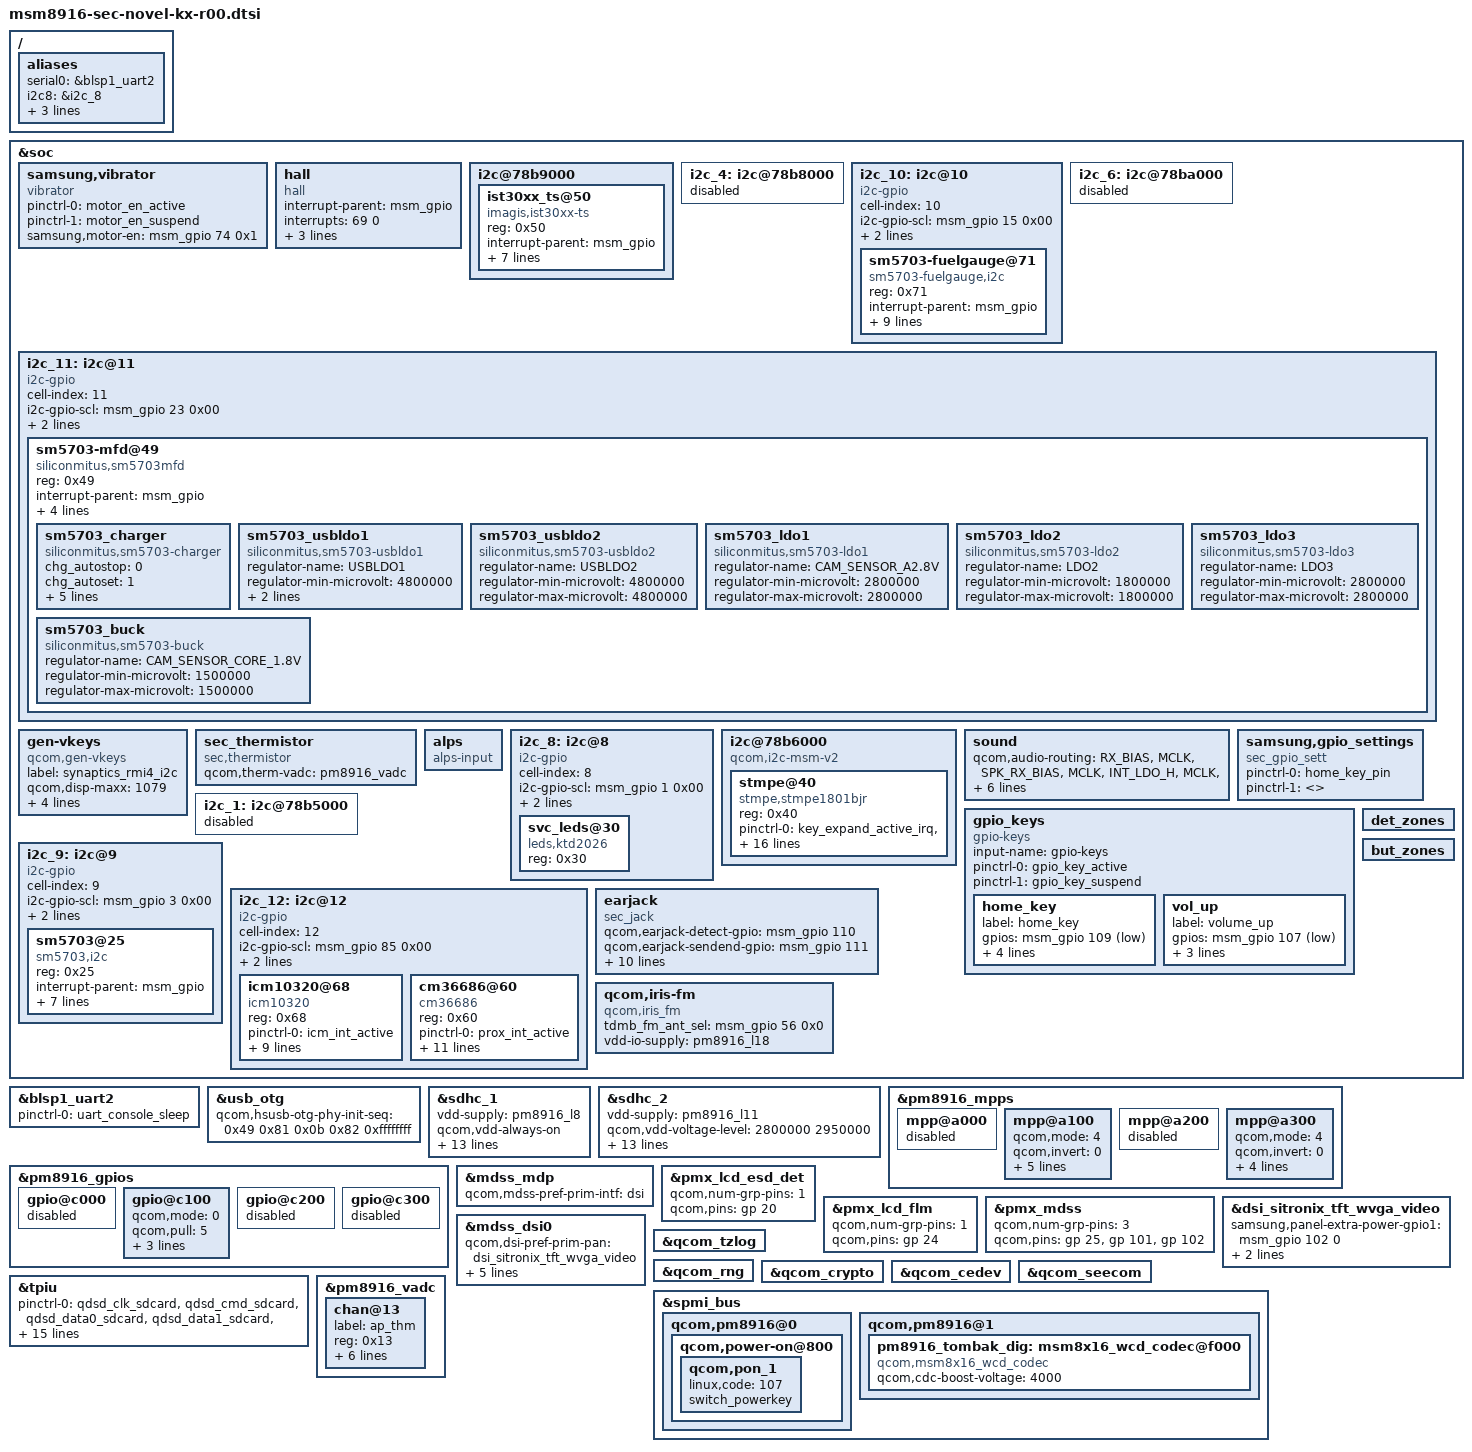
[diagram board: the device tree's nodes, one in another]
/* Copyright (c) 2014, The Linux Foundation. All rights reserved.
 *
 * This program is free software; you can redistribute it and/or modify
 * it under the terms of the GNU General Public License version 2 and
 * only version 2 as published by the Free Software Foundation.
 *
 * This program is distributed in the hope that it will be useful,
 * but WITHOUT ANY WARRANTY; without even the implied warranty of
 * MERCHANTABILITY or FITNESS FOR A PARTICULAR PURPOSE.  See the
 * GNU General Public License for more details.
 */

#include "msm8916.dtsi"
#include "msm8916-pinctrl-sec-novel-kx-r00.dtsi"
#include "msm8916-camera.dtsi"
#include "msm8916-camera-sensor-cdp-novel-r00.dtsi"
#include "msm8916-sec-novel-battery-r00.dtsi"
#include "../../../../../../drivers/video/msm/mdss/samsung/SC7798D_BV038WVM/dsi_panel_SC7798D_BV038WVM_wvga_video.dtsi"
#include "msm8916-tdmb-novel-r00.dtsi"

/ {
	aliases {
		serial0 = &blsp1_uart2;

		/*i2c-gpio bus_id*/
              //i2c7 = &i2c_7;
                i2c8 = &i2c_8;
		i2c9 = &i2c_9;
		i2c10 = &i2c_10;
		i2c11 = &i2c_11;
	};
};

&soc {
	samsung,vibrator {
		pinctrl-names = "tlmm_motor_en_active","tlmm_motor_en_suspend";
		pinctrl-0 = <&motor_en_active>;
		pinctrl-1 = <&motor_en_suspend>;
		compatible = "vibrator";
		samsung,motor-en = <&msm_gpio 74 0x1>;
		status = "ok";
	};

	hall {
		status = "okay";
		compatible = "hall";
		interrupt-parent = <&msm_gpio>;
		interrupts = <69 0>;
		hall,gpio_flip_cover = <&msm_gpio 69 0>;
		pinctrl-names = "pmx_hall_ic_pin";
		pinctrl-0 = <&hall_ic_pin>;
		hall,folder_type;
	};

	i2c@78b9000 { /* BLSP1 QUP5 */
	status = "ok";
		ist30xx_ts@50 {
			compatible = "imagis,ist30xx-ts";
			reg = <0x50>;
			interrupt-parent = <&msm_gpio>;
			interrupts = <13 0>;
			pinctrl-names = "tsp_int_active", "tsp_en_gpio_active", "tsp_en_gpio_suspend";
			pinctrl-0 = <&int_active>;
			pinctrl-1 = <&tsp_en_active>;
			pinctrl-2 = <&tsp_en_suspend>;

			vdd_en-gpio = <&msm_gpio 75 0x01>;
			imagis,irq-gpio = <&msm_gpio 13 0x00>;
			imagis,i2c-pull-up = <1>;
		};
	};

	i2c_4: i2c@78b8000 { /* BLSP1 QUP4 */
		status="disable";
	};

	i2c_10:i2c@10 {
		cell-index = <10>;
		compatible = "i2c-gpio";
		i2c-gpio-scl = <&msm_gpio 15 0x00>;
		i2c-gpio-sda = <&msm_gpio 14 0x00>;
		i2c-gpio,delay-us = <2>;
		#address-cells = <1>;
		#size-cells = <0>;

		sm5703-fuelgauge@71{
			compatible = "sm5703-fuelgauge,i2c";
			reg = <0x71>;
			interrupt-parent = <&msm_gpio>;
			pinctrl-names = "default";
			pinctrl-0 = <&fg_i2c_active &fuel_int_active>;
			fuelgauge,irqf = "IRQF_TRIGGER_FALLING + IRQF_ONESHOT + IRQF_NO_SUSPEND";
			fuelgauge,fuel_int = <&msm_gpio 121 0x1>;
			fuelgauge,capacity_max = <1000>;
			fuelgauge,capacity_max_margin = <50>;
			fuelgauge,capacity_min = <0>;
			fuelgauge,capacity_calculation_type = <0x17>;
			fuelgauge,fuel_alert_soc = <1>;
		};
	};

	i2c_6: i2c@78ba000 { /* BLSP1 QUP6 */
		status="disable";
	};

	i2c_11:i2c@11 {
		cell-index = <11>;
		compatible = "i2c-gpio";
		i2c-gpio-scl = <&msm_gpio 23 0x00>;
		i2c-gpio-sda = <&msm_gpio 22 0x00>;
		i2c-gpio,delay-us = <2>;
		#address-cells = <1>;
		#size-cells = <0>;

		sm5703-mfd@49{
			compatible = "siliconmitus,sm5703mfd";
			reg = <0x49>;
			interrupt-parent = <&msm_gpio>;
			sm5703,irq-gpio = <&msm_gpio 62 0x00>;
			pinctrl-names = "default";
			pinctrl-0 = <&chg_i2c_active &charger_int_active &if_pmic_rst_active &chg_en_active>;
			sm5703,mrstb-gpio = <&msm_gpio 38 0x00>;

			sm5703_charger {
				compatible = "siliconmitus,sm5703-charger";
				chg_autostop = <0>;
				chg_autoset = <1>;
				chg_aiclen = <1>;
				chg_aiclth = <4500>;
				fg_vol_val = <4350>;
				fg_soc_val = <95>;
				fg_curr_avr_val = <150>;
			};

			sm5703_usbldo1 {
				compatible = "siliconmitus,sm5703-usbldo1";
				regulator-name = "USBLDO1"; /* change name by yourself */
				regulator-min-microvolt = <4800000>;
				regulator-max-microvolt = <4800000>; /* max == min then apply_uV = 1 */
				/* regulator-microvolt-offset = < >; optional*/
				/* regulator-boot-on = "yes"; optional, exist = enabled */
				regulator-always-on = "yes";
				/* regulator-ramp-delay = <100>; optional*/

			};
			sm5703_usbldo2 {
				compatible = "siliconmitus,sm5703-usbldo2";
				regulator-name = "USBLDO2"; /* change name by yourself */
				regulator-min-microvolt = <4800000>;
				regulator-max-microvolt = <4800000>; /* max == min then apply_uV = 1 */
				/* regulator-microvolt-offset = < >; optional*/
				/* regulator-boot-on = "yes"; optional, exist = enabled */
				/* regulator-always-on = "yes"; optional, exist = enabled */
				/* regulator-ramp-delay = <100>; optional*/

			};
			sm5703_ldo1 {
				compatible = "siliconmitus,sm5703-ldo1";
				regulator-name = "CAM_SENSOR_A2.8V"; /* change name by yourself */
				regulator-min-microvolt = <2800000>;
				regulator-max-microvolt = <2800000>; /* max == min then apply_uV = 1 */
				/* regulator-microvolt-offset = < >; optional*/
				/* regulator-boot-on = "yes"; optional, exist = enabled */
				/* regulator-always-on = "yes"; optional, exist = enabled */
				/* regulator-ramp-delay = <100>; optional*/
			};

			sm5703_ldo2 {
				compatible = "siliconmitus,sm5703-ldo2";
				regulator-name = "LDO2"; /* change name by yourself */
				regulator-min-microvolt = <1800000>;
				regulator-max-microvolt = <1800000>; /* max == min then apply_uV = 1 */
				/* regulator-microvolt-offset = < >; optional*/
				/* regulator-boot-on = "yes"; optional, exist = enabled */
				/* regulator-always-on = "yes"; optional, exist = enabled */
				/* regulator-ramp-delay = <100>; optional*/
			};

			sm5703_ldo3 {
				compatible = "siliconmitus,sm5703-ldo3";
				regulator-name = "LDO3"; /* change name by yourself */
				regulator-min-microvolt = <2800000>;
				regulator-max-microvolt = <2800000>; /* max == min then apply_uV = 1 */
				/* regulator-microvolt-offset = < >; optional*/
				/* regulator-boot-on = "yes"; optional, exist = enabled */
				/* regulator-always-on = "yes"; optional, exist = enabled */
				/* regulator-ramp-delay = <100>; optional*/
			};

			sm5703_buck {
				compatible = "siliconmitus,sm5703-buck";
				regulator-name = "CAM_SENSOR_CORE_1.8V"; /* change name by yourself */
				regulator-min-microvolt = <1500000>;
				regulator-max-microvolt = <1500000>; /* max == min then apply_uV = 1 */
				/* regulator-microvolt-offset = < >; optional*/
				/* regulator-boot-on = "yes"; optional, exist = enabled */
				/* regulator-always-on = "yes"; optional, exist = enabled */
				/* regulator-ramp-delay = <100>; optional*/
			};
		};
	};

	gen-vkeys {
		compatible = "qcom,gen-vkeys";
		label = "synaptics_rmi4_i2c";
		qcom,disp-maxx = <1079>;
		qcom,disp-maxy = <1919>;
		qcom,panel-maxx = <1079>;
		qcom,panel-maxy = <2084>;
		qcom,key-codes = <158 139 172 217>;
	};

	sec_thermistor {
		compatible = "sec,thermistor";
		qcom,therm-vadc = <&pm8916_vadc>;
	};

	alps {
			compatible = "alps-input";
	};

	i2c_8: i2c@8 {
		cell-index = <8>;
		compatible = "i2c-gpio";
		i2c-gpio-scl = <&msm_gpio 1 0x00>;
		i2c-gpio-sda = <&msm_gpio 0 0x00>;
		i2c-gpio,delay-us = <2>;
		#address-cells = <1>;
		#size-cells = <0>;
		svc_leds@30{
			compatible = "leds,ktd2026";
			reg = <0x30>;
		};
	};

	i2c@78b6000 { /* BLSP1 QUP2 */
		compatible = "qcom,i2c-msm-v2";

		stmpe@40 {
			compatible = "stmpe,stmpe1801bjr";
			reg = <0x40>;
			pinctrl-names = "default";
			pinctrl-0 = <&key_expand_active_irq &key_expand_active_rst>;
			interrupt-parent = <&msm_gpio>;
			interrupts = <34 0>;
			stmpe,vdd-supply = <&pm8916_l5>;
			stmpe,irq_gpio = <&msm_gpio 34 0x00>;
//			stmpe,sda_gpio = <&msm_gpio 6 0x00>;
//			stmpe,scl_gpio = <&msm_gpio 7 0x00>;
//			stmpe,rst_gpio = <&msm_gpio 105 0x00>;
			stmpe,led_en-gpio = <&msm_gpio 108 0x00>;
			stmpe,block_type = <2>; // STMPE1801_BLOCK_GPIO : 1 / STMPE1801_BLOCK_KEY : 2
			stmpe,debounce = <6>; // 30us : 0 / 90us : 2 / 150us : 4 / 210us : 6
			stmpe,freq = <3>; // 60hz : 0 / 30hz : 1 / 15hz : 2 / 275hz : 3
			stmpe,scan_cnt = <2>;
			stmpe,repeat = <0>;
			stmpe,keypad-project = "novel_3x4-keypad";

			keypad,num-rows = <5>;
			keypad,num-columns = <6>;  //  row   colume   keycode
			linux,keymap = <0x000000fe //   0       0     KEY_RECENT(254)
					0x000100ac //   0       1     KEY_HOME(172)
					0x0002009e //   0       2     KEY_BACK(158)
					0x000300e7 //   0       3     KEY_SEND(231)
					0x000400df //   0       4     KEY_CANCEL(223)
					0x00050000 //   0       5     KEY_RESERVED(0)
					0x0100018b //   1       0     KEY_LIST(0x18b)
					0x01010067 //   1       1     KEY_UP(103)
					0x010200d4 //   1       2     KEY_CAMERA(212)
					0x01030002 //   1       3     KEY_1(2)
					0x01040003 //   1       4     KEY_2(3)
					0x01050004 //   1       5     KEY_3(4)
					0x02000069 //   2       0     KEY_LEFT(105)
					0x02010160 //   2       1     KEY_OK(0x160)
					0x0202006a //   2       2     KEY_RIGHT(106)
					0x02030005 //   2       3     KEY_4(5)
					0x02040006 //   2       4     KEY_5(6)
					0x02050007 //   2       5     KEY_6(7)
					0x03000000 //   3       0     KEY_RESERVED(0)
					0x03010000 //   3       1     KEY_RESERVED(0)
					0x03020000 //   3       2     KEY_RESERVED(0)
					0x03030008 //   3       3     KEY_7(8)
					0x03040009 //   3       4     KEY_8(9)
					0x0305000a //   3       5     KEY_9(10)
					0x040001ae //   4       0     KEY_MESSENGER(0x1ae)
					0x0401006c //   4       1     KEY_DOWN(108)
					0x04020244 //   4       2     R_SOFT -> KEY_APPSELECT(0x244)
					0x0403020a //   4       3     KEY_NUMERIC_STAR(0x20a)
					0x0404000b //   4       4     KEY_0(11)
					0x0405020b >;//   4       5     KEY_NUMERIC_POUND(0x20b)
		};
	};

	/* Over-riding model specific changes */
	sound {
		qcom,audio-routing =
			"RX_BIAS", "MCLK",
			"SPK_RX_BIAS", "MCLK",
			"INT_LDO_H", "MCLK",
			"MIC BIAS External", "Handset Mic",
			"MIC BIAS External", "Secondary Mic",
			"AMIC1", "MIC BIAS External",
			"AMIC2", "Headset Mic",
			"AMIC3", "MIC BIAS External";
		pinctrl-names = "cdc_lines_act",
				"cdc_lines_sus";
		pinctrl-0 = <&cdc_pdm_lines_act>;
		pinctrl-1 = <&cdc_pdm_lines_sus>;
	};

	samsung,gpio_settings{
		compatible = "sec_gpio_sett";
		pinctrl-names = "sec_gpio_active","sec_gpio_suspend";
		pinctrl-0 = <&home_key_pin>;
		pinctrl-1 = <>;
	};

};

&blsp1_uart2 {
	status = "ok";
	pinctrl-names = "default";
	pinctrl-0 = <&uart_console_sleep>;
};

&soc {
	gpio_keys {
		compatible = "gpio-keys";
		input-name = "gpio-keys";
		pinctrl-names = "tlmm_gpio_key_active","tlmm_gpio_key_suspend";
		pinctrl-0 = <&gpio_key_active>;
		pinctrl-1 = <&gpio_key_suspend>;

		home_key {
			label = "home_key";
			gpios = <&msm_gpio 109 0x1>;
			linux,input-type = <1>;
			linux,code = <172>;
			gpio-key,wakeup;
			debounce-interval = <15>;
		};
		vol_up {
			label = "volume_up";
			gpios = <&msm_gpio 107 0x1>;
			linux,input-type = <1>;
			linux,code = <115>;
			debounce-interval = <15>;
		};
	};

	i2c_1: i2c@78b5000 { /* BLSP1 QUP1 */
		status="disable";
	};

	i2c_9:i2c@9 { /*SM5703 GPIO-I2C*/
		cell-index = <9>;
		compatible = "i2c-gpio";
		i2c-gpio-scl = <&msm_gpio 3 0x00>;
		i2c-gpio-sda = <&msm_gpio 2 0x00>;
		i2c-gpio,delay-us = <2>;
		#address-cells = <1>;
		#size-cells = <0>;

		sm5703@25{
			compatible = "sm5703,i2c";
			reg = <0x25>;
			interrupt-parent = <&msm_gpio>;
			interrupts= <12 0>;
			sm5703,irq-gpio = <&msm_gpio 12 0x00>;
			sm5703,gpio-sda = <&msm_gpio 2 0x00>;
			sm5703,gpio-scl = <&msm_gpio 3 0x00>;
			sm5703,uarton-gpio = <&msm_gpio 114 0x00>;
			pinctrl-names = "sm5703_i2c_active","sm5703_i2c_suspend";
			pinctrl-0 = <&muic_i2c_active>;
			pinctrl-1 = <&muic_i2c_suspend>;
		};
	};

	i2c_12: i2c@12 {
		cell-index = <12>;
		compatible = "i2c-gpio";
		i2c-gpio-scl = <&msm_gpio 85 0x00>;
		i2c-gpio-sda = <&msm_gpio 84 0x00>;
		i2c-gpio,delay-us = <1>;
		#address-cells = <1>;
		#size-cells = <0>;

		icm10320@68 {
			compatible = "icm10320";
			reg = <0x68>;
			pinctrl-names = "icm_active","icm_suspend";
			pinctrl-0 = <&icm_int_active>;
			pinctrl-1 = <&icm_int_suspend>;
			interrupt-parent = <&msm_gpio>;
			interrupts = <115 0>;
			inv,irq_gpio = <&msm_gpio 115 0x0>;
			inv,int_config = <0>;
			inv,level_shifter = <0>;
			inv,orientation = <1 0 1 0 1 1 1 1 0>;
			inv,vdd-supply = <&pm8916_l17>;
			inv,vio-supply = <&pm8916_l5>;
		};

		cm36686@60 {
			compatible = "cm36686";
			reg = <0x60>;
			pinctrl-names = "prox_active","prox_suspend";
			pinctrl-0 = <&prox_int_active>;
			pinctrl-1 = <&prox_int_suspend>;
			interrupt-parent = <&msm_gpio>;
			interrupts = <113 0>;
			cm36686,irq_gpio = <&msm_gpio 113 0x1>;
			cm36686,leden_gpio = <&msm_gpio 60 0x1>;
			cm36686,default_hi_thd = <14>;
			cm36686,default_low_thd = <8>;
			cm36686,cancel_hi_thd = <10>;
			cm36686,cancel_low_thd = <5>;
			reg_vdd-supply = <&pm8916_l17>;
			reg_vio-supply = <&pm8916_l5>;
			status = "okay";
		};
	};

	det_zones: det_zones {
		#list-det-cells = <4>;
	};

	but_zones: but_zones {
		#list-but-cells = <3>;
	};

	earjack {
		compatible = "sec_jack";
		qcom,earjack-detect-gpio = <&msm_gpio 110 0x0>;
		qcom,earjack-sendend-gpio = <&msm_gpio 111 0x0>;
		qcom,earjack-read-vadc = <&pm8916_vadc>;

		det-zones-list = <&det_zones 0 10000 10 0>,
						 <&det_zones 975 10000 10 0>,
						 <&det_zones 976 10000 10 1>,
						 <&det_zones 1810 10000 10 1>;
		but-zones-list = <&but_zones 0 0 339>,
						 <&but_zones 1 340 479>,
						 <&but_zones 2 480 999>;
		mpp-channel-scaling = <2 1 1>;
		pinctrl-names = "earjack_gpio_active","earjack_gpio_suspend";
		pinctrl-0 = <&earjack_det_act &earjack_switch_act>;
		pinctrl-1 = <&earjack_det_sus &earjack_switch_sus>;
	};

	qcom,iris-fm {
		compatible = "qcom,iris_fm";
		tdmb_fm_ant_sel = <&msm_gpio 56 0x0>;
		vdd-io-supply = <&pm8916_l18>;
	};
};

&usb_otg {
	qcom,hsusb-otg-phy-init-seq =
					<0x49 0x81 0x0b 0x82 0xffffffff>;
};

&sdhc_1 {
	vdd-supply = <&pm8916_l8>;
	qcom,vdd-always-on;
	qcom,vdd-lpm-sup;
	qcom,vdd-voltage-level = <2900000 2900000>;
	qcom,vdd-current-level = <200 400000>;

	vdd-io-supply = <&pm8916_l5>;
	qcom,vdd-io-always-on;
	qcom,vdd-io-lpm-sup;
	qcom,vdd-io-voltage-level = <1800000 1800000>;
	qcom,vdd-io-current-level = <200 60000>;

	pinctrl-names = "active", "sleep";
	pinctrl-0 = <&sdc1_clk_on &sdc1_cmd_on &sdc1_data_on>;
	pinctrl-1 = <&sdc1_clk_off &sdc1_cmd_off &sdc1_data_off>;

	qcom,nonremovable;

	status = "ok";
};

&sdhc_2 {
	vdd-supply = <&pm8916_l11>;
	qcom,vdd-voltage-level = <2800000 2950000>;
	qcom,vdd-current-level = <15000 400000>;

	vdd-io-supply = <&pm8916_l12>;
	qcom,vdd-io-voltage-level = <1800000 2950000>;
	qcom,vdd-io-current-level = <200 50000>;

	pinctrl-names = "active", "sleep";
	pinctrl-0 = <&sdc2_clk_on &sdc2_cmd_on &sdc2_data_on &sdc2_cd_on>;
	pinctrl-1 = <&sdc2_clk_off &sdc2_cmd_off &sdc2_data_off &sdc2_cd_off>;

	#address-cells = <0>;
	interrupt-parent = <&sdhc_2>;
	interrupts = <0 1 2>;
	#interrupt-cells = <1>;
	interrupt-map-mask = <0xffffffff>;
	interrupt-map = <0 &intc 0 125 0
			1 &intc 0 221 0
			2 &msm_gpio 38 0>;
	interrupt-names = "hc_irq", "pwr_irq", "status_irq";
	//cd-gpios = <&msm_gpio 38 0x1>;

	status = "ok";
};

&pm8916_mpps {
	mpp@a000 { /* MPP 1 */
		/* VDD_PX */
		status = "disabled";
	};

	mpp@a100 { /* MPP 2 */
		status = "ok";
		qcom,mode = <4>; // AIN input
		qcom,invert = <0>; //No Invert
		qcom,output-type = <0>; //CMOS
		qcom,vin-sel = <2>; //PM8971_S3 1.8v
		qcom,src-sel = <0>; //MPP Constant
		qcom,ain-route = <1>; // QPNP_PIN_AIN_AMUX_CH6 = 1 for MPP2
		qcom,master-en = <1>; // Function constant
	};

	mpp@a200 { /* MPP 3 */
		/* VREF DAC */
		status = "disabled";
	};

	mpp@a300 { /* MPP 4 */
		status = "ok";
		qcom,mode = <4>; // AIN input
		qcom,invert = <0>; //No Invert
		qcom,output-type = <0>; //CMOS
		qcom,src-sel = <0>; //MPP Constant
		qcom,ain-route = <3>; // QPNP_PIN_AIN_AMUX_CH8 = 3 for MPP4
		qcom,master-en = <1>; // Function constant
	};
};

&pm8916_gpios {
	gpio@c000 { /* GPIO 1 */
		/* Battery UICC Alarm */
		status = "disabled";
	};

	gpio@c100 { /* GPIO 2 */
		/* NFC_CLK_REQ */
		qcom,mode = <0>; /* QPNP_PIN_MODE_DIG_IN */
		qcom,pull = <5>; /* QPNP_PIN_PULL_NO */
		qcom,vin-sel = <2>; /* QPNP_PIN_VIN2 */
		qcom,src-sel = <2>; /* QPNP_PIN_SEL_FUNC_1 */
		qcom,master-en = <1>;
	};

	gpio@c200 { /* GPIO 3 */
		/* External regulator control for WTR */
		status = "disabled";
	};

	gpio@c300 { /* GPIO 4 */
		/* External regulator control for APC */
		status = "disabled";
	};
};

&mdss_mdp {
       qcom,mdss-pref-prim-intf = "dsi";
};

&pmx_lcd_esd_det {
	qcom,num-grp-pins = <1>;
	qcom,pins = <&gp 20>;
};

&pmx_lcd_flm {
	qcom,num-grp-pins = <1>;
	qcom,pins = <&gp 24>;
};

&pmx_mdss {
                 qcom,num-grp-pins = <3>;
                 qcom,pins = <&gp 25>, <&gp 101>, <&gp 102>;
};
&dsi_sitronix_tft_wvga_video {
	samsung,panel-extra-power-gpio1 = <&msm_gpio 102 0>;
	samsung,panel-extra-power-gpio2 = <&msm_gpio 101 0>;
};
&mdss_dsi0 {
	qcom,dsi-pref-prim-pan = <&dsi_sitronix_tft_wvga_video>;
	pinctrl-names = "mdss_default", "mdss_sleep";
	pinctrl-0 = <&mdss_dsi_active &lcd_esd_det_active &lcd_flm_active>;
	pinctrl-1 = <&mdss_dsi_suspend &lcd_esd_det_suspend &lcd_flm_suspend>;
	qcom,platform-reset-gpio = <&msm_gpio 25 0>;
};

&qcom_tzlog {
	status = "okay";
};

&qcom_rng {
	status = "okay";
};

&qcom_crypto {
	status = "okay";
};

&qcom_cedev {
	status = "okay";
};

&qcom_seecom {
	status = "okay";
};

/* CoreSight */
&tpiu {
      pinctrl-names = "sdcard", "trace", "swduart",
		      "swdtrc", "jtag", "spmi";
       /* NIDnT */
      pinctrl-0 = <&qdsd_clk_sdcard &qdsd_cmd_sdcard
                  &qdsd_data0_sdcard &qdsd_data1_sdcard
                  &qdsd_data2_sdcard &qdsd_data3_sdcard>;
      pinctrl-1 = <&qdsd_clk_trace &qdsd_cmd_trace
                  &qdsd_data0_trace &qdsd_data1_trace
                  &qdsd_data2_trace &qdsd_data3_trace>;
      pinctrl-2 = <&qdsd_cmd_swduart &qdsd_data0_swduart
                  &qdsd_data1_swduart &qdsd_data2_swduart
                  &qdsd_data3_swduart>;
      pinctrl-3 = <&qdsd_clk_swdtrc &qdsd_cmd_swdtrc
                  &qdsd_data0_swdtrc &qdsd_data1_swdtrc
                  &qdsd_data2_swdtrc &qdsd_data3_swdtrc>;
      pinctrl-4 = <&qdsd_cmd_jtag &qdsd_data0_jtag
                  &qdsd_data1_jtag &qdsd_data2_jtag
                  &qdsd_data3_jtag>;
      pinctrl-5 = <&qdsd_clk_spmi &qdsd_cmd_spmi
                  &qdsd_data0_spmi &qdsd_data3_spmi>;
};

&pm8916_vadc {
	chan@13 {
		label = "ap_thm";
		reg = <0x13>; // channel 19 for MPP4 , 1:1scale
		qcom,decimation = <0>;
		qcom,pre-div-channel-scaling = <0>; // 1:1scale
		qcom,calibration-type = "ratiometric";
		qcom,scale-function = <1>;
		qcom,hw-settle-time = <2>;
		qcom,fast-avg-setup = <0>;
	};
};

&spmi_bus {
	qcom,pm8916@0 {
		qcom,power-on@800 {
			qcom,pon_1 {
				linux,code = <107>;
				switch_powerkey;
			};
		};
	};
	qcom,pm8916@1 {
		pm8916_tombak_dig: msm8x16_wcd_codec@f000{
			compatible = "qcom,msm8x16_wcd_codec";
			qcom,cdc-boost-voltage = <4000>; //boost voltage
		};
	};
};
